# ECD3_MMR_ICONT register map
Vendor: Texas Instruments
Peripheral module from a debugger description file (folder omap5430_ES2_PUBLIC).
Registers are 32-bit, access per field, reset 0x0 unless marked. A register's access mark holds for its fields unless they carry their own. Offsets are as the file gives them; lines under a group give offsets from that group; [hi:lo] are bit positions; {n}, {i} and the like mark numbered series; 'fields as' and 'values as' point back to an identical list; <NAME> marks a mode.

## ECD3_MMR_ICONT (part 1 of 2)
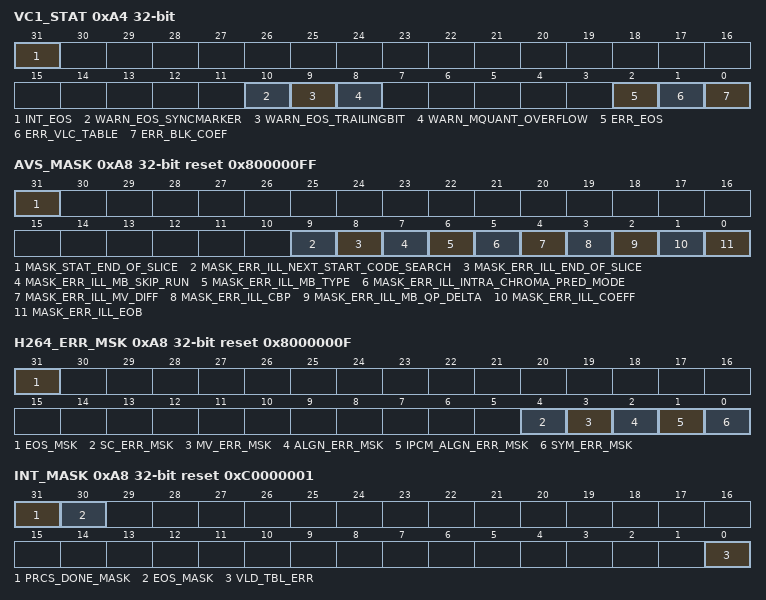
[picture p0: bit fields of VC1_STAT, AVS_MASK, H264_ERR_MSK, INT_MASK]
0xA4 VC1_STAT ro
  [31] INT_EOS — Read 0x1: An end-of-slice symbol was found.
  [10] WARN_EOS_SYNCMARKER — This issue is raised when ECD3 cannot find syncmarker header syntax even though a single-bit just after decoding last MB is equal to 0.
  [9] WARN_EOS_TRAILINGBIT — Read 0x1: ECD3 cannot detect the presence of the trailing bit even though the next start code was detected. Even though ECD3 found this defect, the ECD3 will start to search next start code.
  [8] WARN_MQUANT_OVERFLOW — warn_mquant_overflow Read 0x0: MQUANT does not overflow Read 0x1: MQUANT overflow
  [2] ERR_EOS — err_eos indicates an error during search processing for next start code.
  [1] ERR_VLC_TABLE — err_vlc_table indicates when the following irregular cases happen. - Total RUN of AC coefficient exceeds a limit of block size
  [0] ERR_BLK_COEF — err_blk_coef indicates when the following irregular cases happen
0xA8 AVS_MASK ro reset 0x800000FF
  [31] MASK_STAT_END_OF_SLICE — Mask flags correspond to status bits
  [9] MASK_ERR_ILL_NEXT_START_CODE_SEARCH — Mask flags correspond to status bits
  [8] MASK_ERR_ILL_END_OF_SLICE — Mask flags correspond to status bits
  [7] MASK_ERR_ILL_MB_SKIP_RUN — Mask flags correspond to status bits
  [6] MASK_ERR_ILL_MB_TYPE — Mask flags correspond to status bits
  [5] MASK_ERR_ILL_INTRA_CHROMA_PRED_MODE — Mask flags correspond to status bits
  [4] MASK_ERR_ILL_MV_DIFF — Mask flags correspond to status bits
  [3] MASK_ERR_ILL_CBP — Mask flags correspond to status bits
  [2] MASK_ERR_ILL_MB_QP_DELTA — Mask flags correspond to status bits
  [1] MASK_ERR_ILL_COEFF — Mask flags correspond to status bits
  [0] MASK_ERR_ILL_EOB — Mask flags correspond to status bits
0xA8 H264_ERR_MSK reset 0x8000000F — H.264 MASK register
  [31] EOS_MSK ro — EOS_MSK = 1 enables detection of an EOS.
  [4] SC_ERR_MSK ro — SC_ERR_MSK = 0 (fixed) which indicates that int_err will never be issued on detecting start code search error.
  [3] MV_ERR_MSK ro — MV_ERR_MSK = 1 enables detection of mv errors (MV_ERR).
  [2] ALGN_ERR_MSK rw — ALGN_ERR_MSK = 1 enables detection of CABAC alignment bits errors (ALGN_ERR)
  [1] IPCM_ALGN_ERR_MSK rw — IPCM_ALGN_ERR_MSK = 1 enables detection of I_PCM alignment bits errors (IPCM_ALGN_ERR)
  [0] SYM_ERR_MSK ro — SYM_ERR_MSK = 1 enables detections of all other bitstream errors (SYM_ERR).
0xA8 INT_MASK ro reset 0xC0000001
  [31] PRCS_DONE_MASK — Mask register for prcs_done signal. 0: PRCS_DONE signal disable. 1: PRCS_DONE signal enable
  [30] EOS_MASK — Mask register for eos_done pulse signal 0: EOS_DONE signal disable. 1: EOS_DONE signal enable.
  [0] VLD_TBL_ERR — Mask register for control of error interrupt assertion. 0: no error interrupt is asserted though condition is hit. 1: error interrupt is asserted if condition is hit.
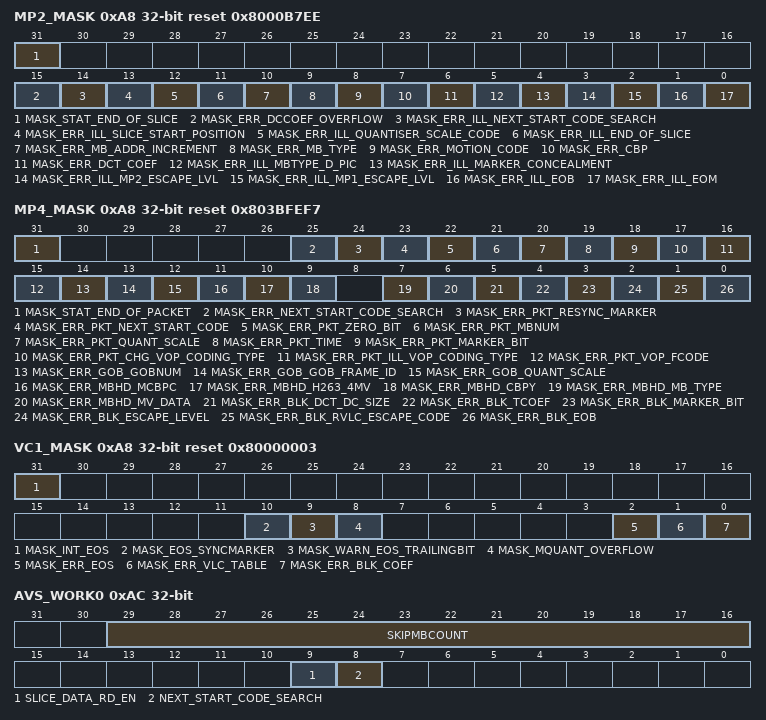
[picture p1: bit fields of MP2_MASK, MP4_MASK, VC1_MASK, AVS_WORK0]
0xA8 MP2_MASK reset 0x8000B7EE
  [31] MASK_STAT_END_OF_SLICE ro — Mask flags correspond to status bits
  [15] MASK_ERR_DCCOEF_OVERFLOW ro — Mask flags correspond to status bits
  [14] MASK_ERR_ILL_NEXT_START_CODE_SEARCH ro — Mask flags correspond to status bits
  [13] MASK_ERR_ILL_SLICE_START_POSITION ro — Mask flags correspond to status bits
  [12] MASK_ERR_ILL_QUANTISER_SCALE_CODE ro — Mask flags correspond to status bits
  [11] MASK_ERR_ILL_END_OF_SLICE ro — Mask flags correspond to status bits
  [10] MASK_ERR_MB_ADDR_INCREMENT ro — Mask flags correspond to status bits
  [9] MASK_ERR_MB_TYPE ro — Mask flags correspond to status bits
  [8] MASK_ERR_MOTION_CODE ro — Mask flags correspond to status bits
  [7] MASK_ERR_CBP ro — Mask flags correspond to status bits
  [6] MASK_ERR_DCT_COEF ro — Mask flags correspond to status bits
  [5] MASK_ERR_ILL_MBTYPE_D_PIC ro — Mask flags correspond to status bits
  [4] MASK_ERR_ILL_MARKER_CONCEALMENT rw — Mask flags correspond to status bits
  [3] MASK_ERR_ILL_MP2_ESCAPE_LVL ro — Mask flags correspond to status bits
  [2] MASK_ERR_ILL_MP1_ESCAPE_LVL ro — Mask flags correspond to status bits
  [1] MASK_ERR_ILL_EOB ro — Mask flags correspond to status bits
  [0] MASK_ERR_ILL_EOM rw — Mask flags correspond to status bits
0xA8 MP4_MASK reset 0x803BFEF7
  [31] MASK_STAT_END_OF_PACKET ro — Mask flags correspond to status bits
  [25] MASK_ERR_NEXT_START_CODE_SEARCH ro — Mask flags correspond to status bits
  [24] MASK_ERR_PKT_RESYNC_MARKER ro — Mask flags correspond to status bits
  [23] MASK_ERR_PKT_NEXT_START_CODE ro — Mask flags correspond to status bits
  [22] MASK_ERR_PKT_ZERO_BIT ro — Mask flags correspond to status bits
  [21] MASK_ERR_PKT_MBNUM ro — Mask flags correspond to status bits
  [20] MASK_ERR_PKT_QUANT_SCALE ro — Mask flags correspond to status bits
  [19] MASK_ERR_PKT_TIME ro — Mask flags correspond to status bits
  [18] MASK_ERR_PKT_MARKER_BIT rw — Mask flags correspond to status bits
  [17] MASK_ERR_PKT_CHG_VOP_CODING_TYPE ro — Mask flags correspond to status bits
  [16] MASK_ERR_PKT_ILL_VOP_CODING_TYPE ro — Mask flags correspond to status bits
  [15] MASK_ERR_PKT_VOP_FCODE ro — Mask flags correspond to status bits
  [14] MASK_ERR_GOB_GOBNUM ro — Mask flags correspond to status bits
  [13] MASK_ERR_GOB_GOB_FRAME_ID ro — Mask flags correspond to status bits
  [12] MASK_ERR_GOB_QUANT_SCALE ro — Mask flags correspond to status bits
  [11] MASK_ERR_MBHD_MCBPC ro — Mask flags correspond to status bits
  [10] MASK_ERR_MBHD_H263_4MV ro — Mask flags correspond to status bits
  [9] MASK_ERR_MBHD_CBPY ro — Mask flags correspond to status bits
  [7] MASK_ERR_MBHD_MB_TYPE ro — Mask flags correspond to status bits
  [6] MASK_ERR_MBHD_MV_DATA ro — Mask flags correspond to status bits
  [5] MASK_ERR_BLK_DCT_DC_SIZE ro — Mask flags correspond to status bits
  [4] MASK_ERR_BLK_TCOEF ro — Mask flags correspond to status bits
  [3] MASK_ERR_BLK_MARKER_BIT rw — Mask flags correspond to status bits
  [2] MASK_ERR_BLK_ESCAPE_LEVEL ro — Mask flags correspond to status bits
  [1] MASK_ERR_BLK_RVLC_ESCAPE_CODE ro — Mask flags correspond to status bits
  [0] MASK_ERR_BLK_EOB ro — Mask flags correspond to status bits
0xA8 VC1_MASK reset 0x80000003
  [31] MASK_INT_EOS ro
  [10] MASK_EOS_SYNCMARKER ro
  [9] MASK_WARN_EOS_TRAILINGBIT ro — Reserved
  [8] MASK_MQUANT_OVERFLOW rw — Mask flags correspond to status bits
  [2] MASK_ERR_EOS ro — Mask flags correspond to status bits
  [1] MASK_ERR_VLC_TABLE ro — Mask flags correspond to status bits
  [0] MASK_ERR_BLK_COEF ro — Mask flags correspond to status bits
0xAC AVS_WORK0
  [29:16] SKIPMBCOUNT rw — SkipMbCount This field specifies SkipMbCount described in AVS standard section 9.3.
  [9] SLICE_DATA_RD_EN rw — Slice data read enable flag 0: slice data is read only at the first macroblock in a slice 1: slice data is read at every macroblocks AVS RTL can reduce the cycle not to read slice data in non-first macroblock in a slice by clearing this flag to 0. For normal bitstream encode and decode case, this bit must be cleared to 0 for faster execution of AVS. But if user wants to start processing from the non-first macroblock in a slice, user must set this flag to 1. This flag is applicable for RTL, not C-model. C-model always read slice data because there is no static data register in C-model. Then, the behavior between RTL and C-model is not matched if this flag is cleared to 0 and the processing is started from the non-first macroblock in a slice.
  [8] NEXT_START_CODE_SEARCH rw — next_start_code_search This field specifies ECD starts start code search or not when error is occurred. 0: non-search 1: search
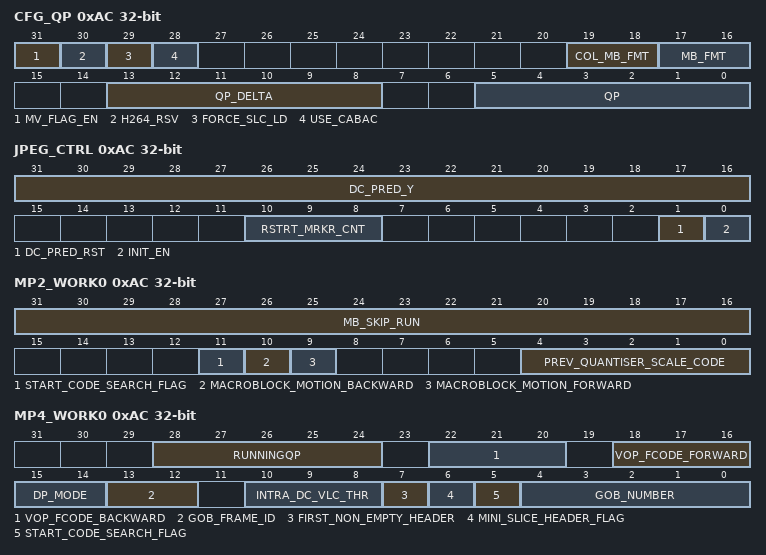
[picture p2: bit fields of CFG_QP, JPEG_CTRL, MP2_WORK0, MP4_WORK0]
0xAC CFG_QP
  [31] MV_FLAG_EN rw — MV_FLAG_EN =1 enables motion vector and reference index comparison in decoding. If MV_FLAG_EN=1, motion vectors and reference indices are compared and results are reflected to mv_equal_flag_l0/1 and refidx_equal_flag_l0/1 in MBinfo. In encoding, even if MV_FLAG_EN=1, the comparisons are not executed.
  [30] H264_RSV rw — Reserved for future use
  [29] FORCE_SLC_LD rw — FORCE_SLC_LD = 1 forces slice information data loading from memory for each macroblock process. If this bit is equal to 0, slice information data is loaded only when the current macroblock is the first macroblock in the slice. This feature is for debug use only so as to enable modifying slice information in the middle of slice processing. Usually, it is necessary at the beginning of each slice, and this bit must be cleared to save cycle counts for data loading
  [28] USE_CABAC ro — USE_CABAC = 1 indicates that the CABAC is in use for entropy coding. If the value is equal to 0, CAVLC is used. The ECD3 automatically loads the value from slice information onto this register.
  [19:18] COL_MB_FMT ro — COL_MB_FMT indicates the macroblock header format type for the co-located macroblock data. 00b : Bi-16-MV format 01b : 16-MV format 10b : Bi-4-MV format 11b : The reserved ECD3 automatically loads the value from slice information onto this register
  [17:16] MB_FMT ro — MB_FMT indicates the macroblock header format type for the current macroblock and neighboring macroblocks in the current picture. 00b : Bi-16-MV format 01b : 16-MV format 10b : Bi-4-MV format 11b : The reserved ECD3 automatically loads the value from slice information onto this register
  [13:8] QP_DELTA rw — QP_DELTA is equal to mb_qp_delta of the last macroblock decoded or encoded. This register value is maintained by the ECD3, so that the user does not set up the value
  [5:0] QP rw — QP is equal to the quantizer parameter for the last macroblock decoded or encoded. This register value is maintained by the ECD3
0xAC JPEG_CTRL — JPEG Control register
  [31:16] DC_PRED_Y rw — Luminance DC prediction value is stored in register. H/W regards this value as previous DC value (source of DC prediction) except in a block just after restart marker. In case other than tests, this register value must not be written.
  [10:8] RSTRT_MRKR_CNT ro — Restart marker counter value (during encoding only) is reflected in this register. In decoding, please ignore.
  [1] DC_PRED_RST rw — If this register bit is high, DC prediction for the first block of the current MCU is not executed. This register bit must be used in case of error recovery, and valid in decoder. In encoder, the configured value is ignored. The configured value is automatically reset immediately after the user configures this bit to 1. 0: DC prediction is executed. 1: DC prediction is reset.
  [0] INIT_EN rw — This bit controls initialization of JPEG core on ECD module. If this bit is high, all counter values are reset and all address pointer for picture configuration data and Huffman code tables are loaded. Please notice that this bit must be activated once before starting processing of ECD module, and after all configuration of memory address is done. During period that this bit is high, any writing access is ignored. 0: initialize disable. 1: initialize start.
0xAC MP2_WORK0
  [31:16] MB_SKIP_RUN rw — Specifies the number of macroblocks to be skipped
  [11] START_CODE_SEARCH_FLAG rw — Specifies whether ECD starts searching next start code or not when error is occurred in decoding. 0: Not search next start code 1: Search next start code In encoding, this field must be 0.
  [10] MACROBLOCK_MOTION_BACKWARD rw — Specifies macroblock_motion_backward described in MPEG-2 standard section 6.3.17.1.
  [9] MACROBLOCK_MOTION_FORWARD rw — Specifies macroblock_motion_forward described in MPEG-2 standard section 6.3.17.1.
  [4:0] PREV_QUANTISER_SCALE_CODE rw — Specifies previous macroblock's quantizer_scale_code described in MPEG-2 standard section 6.3.16
0xAC MP4_WORK0
  [28:24] RUNNINGQP rw — This field is used for reserving runningQp for the next macroblock, not showing the current macroblock's quantizer_scale. At the beginning of a VOP, ECD copies from vop_quant in VOP header information
  [22:20] VOP_FCODE_BACKWARD rw — These fields specify vop_fcode_forward and vop_fcode_backward updated at packet header. In decoding, at the beginning of a VOP, ECD copies from vop_fcode_forward and vop_fcode_backward in VOP header information to these fields. ECD updates these fields at packet header decoding. In encoding, this field is not used and must be fixed to 0. ECD uses vop_fcode_forward and vop_fcode_backward in macroblock header information
  [18:16] VOP_FCODE_FORWARD rw — These fields specify vop_fcode_forward and vop_fcode_backward updated at packet header. In decoding, at the beginning of a VOP, ECD copies from vop_fcode_forward and vop_fcode_backward in VOP header information to these fields. ECD updates these fields at packet header decoding. In encoding, this field is not used and must be fixed to 0. ECD uses vop_fcode_forward and vop_fcode_backward in macroblock header information
  [15:14] DP_MODE rw — This field indicates which data is encoding or decoding in data partitioning mode. Host must reset this field to 0 at the beginning of a VOP. ECD updates automatically during a VOP. This field is reset to 0 at the beginning of a slice, and ECD automatically sets to 1 when it decodes or encodes dc_marker or motion_marker, and also automatically sets to 2 when it decodes all texture header. 0: GOB header or motion and header information processing 1: texture header processing 2: TCOEF processing or packet header, In non data partitioning mode, this field is not used
  [13:12] GOB_FRAME_ID rw — This field specifies gob_frame_id which is updated at gob header. In decoding, when first_non_empty_header = 1, decoded gob_frame_id in packet header is compared with gob_frame_id in local information, and if it differs, ECD detects error named 'gob_frame_id is changed'. When first_non_empty_header = 0, decoded gob_frame_id is written to this field. If GOB header is not existed in a VOP, gob_frame_id is 0. In encoding, this field is not used and must be fixed to 0. ECD uses gob_frame_id in macroblock header information
  [10:8] INTRA_DC_VLC_THR rw — This is a 3-bit code that specifies a threshold value of quantizer scale used to switch between two VLC's for coding of Intra DC coefficients. In decoding, at the beginning of a VOP, ECD copies from intra_dc_vlc_thr in VOP header information to the field. ECD updates the fields at packet header decoding. In encoding, this field is not used. ECD uses intra_dc_vlc_thr in macroblock header information
  [7] FIRST_NON_EMPTY_HEADER rw — This is the flag to indicate the first non empty GOB header or not. In decoding, ECD sets 1 to this field at the beginning of VOP. ECD sets to 0 if ECD encounters the first non-empty GOB header. In encoding, this field is not used and must be fixed to 0
  [6] MINI_SLICE_HEADER_FLAG rw — In H.263 decoding, this field specifies whether the current slice header is mini slice header or not. After decoding slice header, this field is automatically reset to 0 by the ECD3. 0: non mini slice header 1: mini slice header Otherwise, this field must be 0
  [5] START_CODE_SEARCH_FLAG rw — In decoding, this field specifies whether ECD starts searching next_start_code and resync_marker or not when error is occurred in decoding. 0: Not search next start code and resync marker 1: Search next start code and resync marker In encoding, this field must be 0
  [4:0] GOB_NUMBER rw — In decoding, this field specifies gob_number of the current macroblock. In encoding, this field is not used and must be fixed to 0
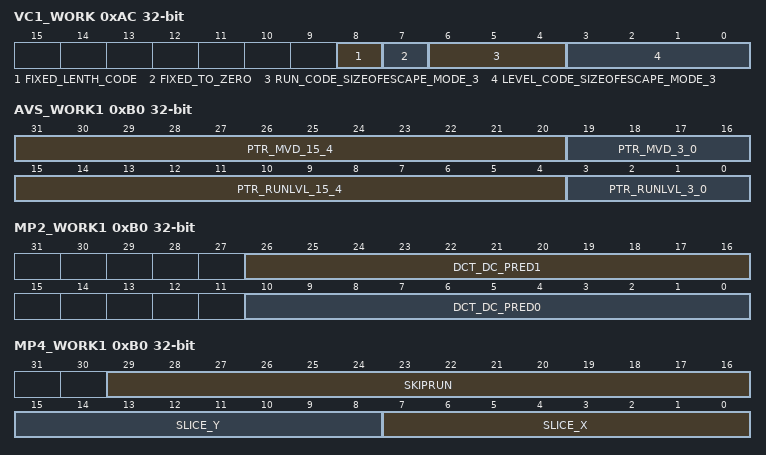
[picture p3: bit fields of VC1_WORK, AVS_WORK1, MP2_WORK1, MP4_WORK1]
0xAC VC1_WORK
  [8] FIXED_LENTH_CODE rw — Presence of Fixed Length Code (escape mode 3) Setting 1 specifies the first case of escape mode 3 in a frame. This register is cleared when found ESCAPE3. 0: non-first case of escape mode 3 in frame 1: first case of escape mode 3 in frame
  [7] FIXED_TO_ZERO ro
  [6:4] RUN_CODE_SIZEOFESCAPE_MODE_3 rw — Run code size of escape mode 3 Run code size of escape mode 3 In decoding, this register is automatically updated when presence of fixed length code is cleared to 0
  [3:0] LEVEL_CODE_SIZEOFESCAPE_MODE_3 rw — Level code size of escape mode 3 Level code size of escape mode 3 In decoding, this register is automatically updated when presence of fixed length code is cleared to 0
0xB0 AVS_WORK1
  [31:20] PTR_MVD_15_4 rw — PTR_MVD Start address of temporary MVD info. This value must be multiple of 8.
  [19:16] PTR_MVD_3_0 ro — PTR_MVD Start address of temporary MVD info. This value must be multiple of 8.
  [15:4] PTR_RUNLVL_15_4 rw — PTR_RUNLVL Start address of temporary run level info. This value must be multiple of 8.
  [3:0] PTR_RUNLVL_3_0 ro — PTR_RUNLVL Start address of temporary run level info. This value must be multiple of 8.
0xB0 CDC_VP_4
  [15:3] ACPREDPTR_15_3 rw — ACPREDPTR I picture except simple/main I picture
0xB0 MP2_WORK1
  [26:16] DCT_DC_PRED1 rw — In decoding, this value specifies dct_dc_pred[1] described in MPEG-2 standard section 7.2.1. In encoding, this value is fixed to 0
  [10:0] DCT_DC_PRED0 rw — In decoding, this value specifies dct_dc_pred[0] described in MPEG-2 standard section 7.2.1. In encoding, this value is fixed to 0
0xB0 MP4_WORK1
  [29:16] SKIPRUN rw — In the case of B-VOP decoding, if decoded macroblock_number in video_packet_header &gt; the macroblock address counter, ECD notices the macroblocks from the macroblock address counter to macroblock_number -1 would be not_coded macroblock. ECD reserves (macroblock_number - MB_NUM) value to SKIP_NUM to skip macroblocks. In the other cases, this field must be 0
  [15:8] SLICE_Y rw — In data partitioning, this field shows the position of the first macroblock in a slice. Otherwise, this field must be 0. This is for data partitioning to recover the first macroblock position after texture encoding and decoding
  [7:0] SLICE_X rw — In data partitioning, this field shows the position of the first macroblock in a slice. Otherwise, this field must be 0. This is for data partitioning to recover the first macroblock position after texture encoding and decoding
0xB0 SKIP_RUN
  [15:0] SKIP_RUN_NB rw — SKIP_RUN_NB indicates the number of skipped macroblocks left in CAVLC. This register is maintained by the ECD3.
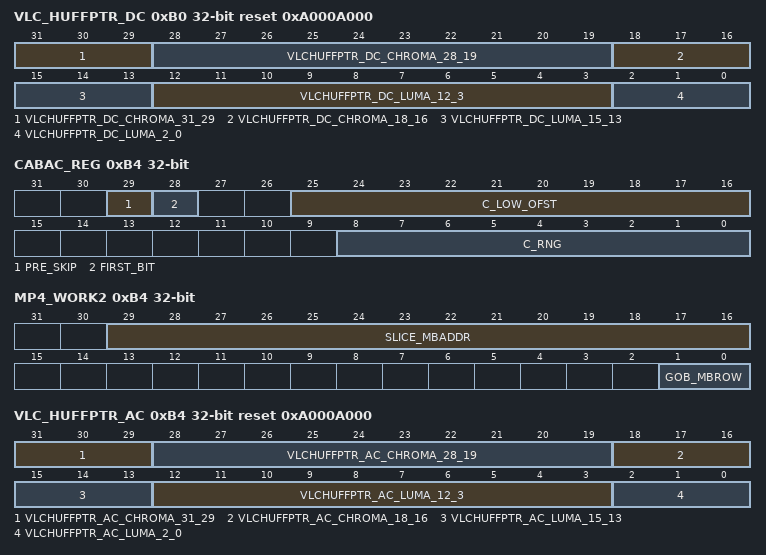
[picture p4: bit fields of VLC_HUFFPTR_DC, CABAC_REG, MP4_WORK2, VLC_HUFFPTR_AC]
0xB0 VLC_HUFFPTR_DC reset 0xA000A000 — Pointers to Huffman table for VLC DC components
  [31:29] VLCHUFFPTR_DC_CHROMA_31_29 ro — Indicating start address of Huffman table for VLC DC Chroma. The address value must be aligned to 64-bit word boundary
  [28:19] VLCHUFFPTR_DC_CHROMA_28_19 rw — Indicating start address of Huffman table for VLC DC Chroma. The address value must be aligned to 64-bit word boundary
  [18:16] VLCHUFFPTR_DC_CHROMA_18_16 ro — Indicating start address of Huffman table for VLC DC Chroma. The address value must be aligned to 64-bit word boundary
  [15:13] VLCHUFFPTR_DC_LUMA_15_13 ro — Indicating start address of Huffman table for VLC DC-luma. The address value must be aligned to 64-bit word boundary
  [12:3] VLCHUFFPTR_DC_LUMA_12_3 rw — Indicating start address of Huffman table for VLC DC-luma. The address value must be aligned to 64-bit word boundary
  [2:0] VLCHUFFPTR_DC_LUMA_2_0 ro — Indicating start address of Huffman table for VLC DC-luma. The address value must be aligned to 64-bit word boundary
0xB4 CABAC_REG
  [29] PRE_SKIP rw — PRE_SKIP = 1 indicates that both top and bottom macroblocks in MB-AFF mode decoding are skipped. This flag is not used in encoding or in CAVLC mode
  [28] FIRST_BIT rw — FIRST_BIT = 1 indicates that the next bit put by CABAC is the first bit since the last CABAC initialization. This register is automatically set by CABAC encoder. This flag is ignored in decoding or in CAVLC mode
  [25:16] C_LOW_OFST rw — C_LOW_OFST is equal to codILow in encoding, and codIOffset in decoding. codILow shall be in the range of [0x000, 0x3FF], and codIOffset in [0x000, 0x1FF]. This field is ignored in CAVLC
  [8:0] C_RNG rw — C_RNG is equal to codIRange. This field is ignored in CAVLC
0xB4 CDC_VP_5
  [15:3] OVERFLAGPTR_15_3 rw — OVERFLAGPTR I picture except simple/main I picture
0xB4 MP2_WORK2
  [10:0] DCT_DC_PRED2 rw — In decoding, this value specifies dct_dc_pred[2] described in MPEG-2 standard section 7.2.1. In encoding, this value is fixed to 0
0xB4 MP4_WORK2
  [29:16] SLICE_MBADDR rw — In data partition decoding, this field shows the macroblock address of the first macroblock in the current slice. ECD updates this field at the beginning of a slice. The value is used to recover the first macroblock position in data partitioning. Otherwise, this field must be 0
  [1:0] GOB_MBROW rw — In the case h263_mode = 1 and decoding, this field shows the vertical position of current macroblock in a slice or GOB. For example gob_mbrow = 0 means the current macroblock is in the first row of the current slice or GOB. In the other cases, this field is fixed to 0
0xB4 VLC_HUFFPTR_AC reset 0xA000A000 — Pointers to Huffman table for VLC AC components
  [31:29] VLCHUFFPTR_AC_CHROMA_31_29 ro — Indicating start address of Huffman table for VLC AC Chroma. The address value must be aligned to 64-bit word boundary
  [28:19] VLCHUFFPTR_AC_CHROMA_28_19 rw — Indicating start address of Huffman table for VLC AC Chroma. The address value must be aligned to 64-bit word boundary
  [18:16] VLCHUFFPTR_AC_CHROMA_18_16 ro — Indicating start address of Huffman table for VLC AC Chroma. The address value must be aligned to 64-bit word boundary
  [15:13] VLCHUFFPTR_AC_LUMA_15_13 ro — Indicating start address of Huffman table for VLC AC-luma. The address value must be aligned to 64-bit word boundary
  [12:3] VLCHUFFPTR_AC_LUMA_12_3 rw — Indicating start address of Huffman table for VLC AC-luma. The address value must be aligned to 64-bit word boundary
  [2:0] VLCHUFFPTR_AC_LUMA_2_0 ro — Indicating start address of Huffman table for VLC AC-luma. The address value must be aligned to 64-bit word boundary
0xB8 CDC_VP_6
  [15:3] MVMODEPTR_15_3 rw — MVMODEPTR Progressive P picture
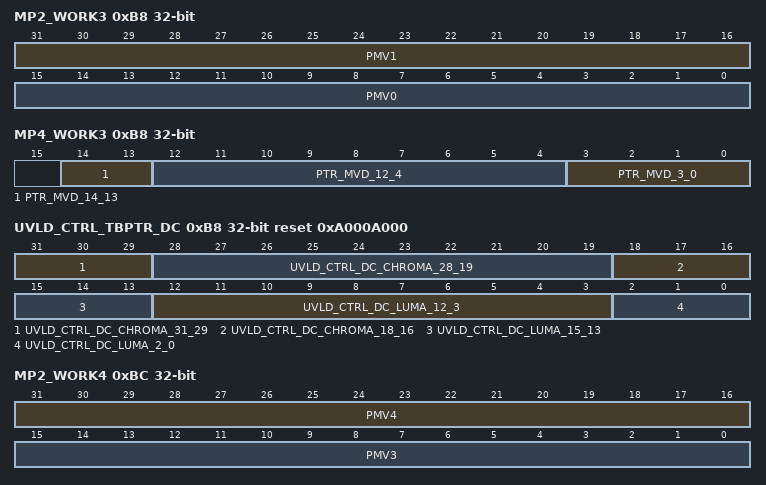
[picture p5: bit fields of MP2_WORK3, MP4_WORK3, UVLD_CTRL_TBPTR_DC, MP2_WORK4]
0xB8 MP2_WORK3 rw
  [31:16] PMV1 — Specifies PMV[0][0][1] described in MPEG-2 standard section 7.6.3. They are half-pel precision
  [15:0] PMV0 — Specifies PMV[0[0][0] described in MPEG-2 standard section 7.6.3. They are half-pel precision
0xB8 MP4_WORK3
  [14:13] PTR_MVD_14_13 ro — This field specifies temporary MVD data pointer. Temporary MVD data must be located at ECDWBUF
  [12:4] PTR_MVD_12_4 rw — This field specifies temporary MVD data pointer. Temporary MVD data must be located at ECDWBUF
  [3:0] PTR_MVD_3_0 ro — This field specifies temporary MVD data pointer. Temporary MVD data must be located at ECDWBUF
0xB8 SYM_CNT rw
  [31:0] SYM_CNT_NB — SYM_CNT_NB is equal to the total number of CABAC bin symbols encoded since the last CABAC initialization. This register is reset to 0 when H.264 core is invoked for a first macroblock in a slice. This register is not used in decoding or in CAVLC mode. This register is maintained by the ECD3
0xB8 UVLD_CTRL_TBPTR_DC reset 0xA000A000 — Pointers to control table for UVLD DC components
  [31:29] UVLD_CTRL_DC_CHROMA_31_29 ro — Indicating start address of control table for UVLD DC-chroma. The address value must be aligned to 64-bit word boundary
  [28:19] UVLD_CTRL_DC_CHROMA_28_19 rw — Indicating start address of control table for UVLD DC-chroma. The address value must be aligned to 64-bit word boundary
  [18:16] UVLD_CTRL_DC_CHROMA_18_16 ro — Indicating start address of control table for UVLD DC-chroma. The address value must be aligned to 64-bit word boundary
  [15:13] UVLD_CTRL_DC_LUMA_15_13 ro — Indicating start address of control table for UVLD DC-luma. The address value must be aligned to 64-bit word boundary.
  [12:3] UVLD_CTRL_DC_LUMA_12_3 rw — Indicating start address of control table for UVLD DC-luma. The address value must be aligned to 64-bit word boundary.
  [2:0] UVLD_CTRL_DC_LUMA_2_0 ro — Indicating start address of control table for UVLD DC-luma. The address value must be aligned to 64-bit word boundary.
0xBC BITS_OSTD rw
  [31:0] BITS_OSTD_NB — BITS_OSTD_NB is equal to the total number of outstanding bits in CABAC encoder. This register is not used in decoding or in CAVLC mode. This register is maintained by the ECD3
0xBC CDC_VP_7
  [15:3] SKIPMBPTR_15_3 rw — SKIPMBPTR Progressive P/B picture, Interlace Frame P/B picture
0xBC MP2_WORK4 rw
  [31:16] PMV4 — Specifies PMV[0][1][1] described in MPEG-2 standard section 7.6.3. They are half-pel precision
  [15:0] PMV3 — Specifies PMV[0][1][0] described in MPEG-2 standard section 7.6.3. They are half-pel precision
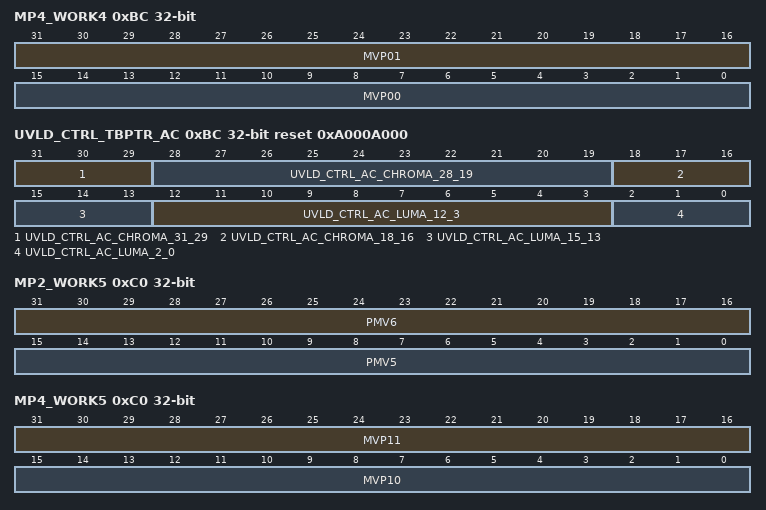
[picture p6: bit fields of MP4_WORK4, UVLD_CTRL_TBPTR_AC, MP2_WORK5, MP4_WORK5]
0xBC MP4_WORK4 rw
  [31:16] MVP01 — MVP[0][1]: Motion Vector Predictors for B-VOP (field forward top motion vector predictor)
  [15:0] MVP00 — MVP[0][0]: Motion Vector Predictors for B-VOP (field forward top motion vector predictor)
0xBC UVLD_CTRL_TBPTR_AC reset 0xA000A000 — Pointers to control table for UVLD AC components
  [31:29] UVLD_CTRL_AC_CHROMA_31_29 ro — Indicating start address of control table for UVLD AC-chroma. The address value must be aligned to 64-bit word boundary
  [28:19] UVLD_CTRL_AC_CHROMA_28_19 rw — Indicating start address of control table for UVLD AC-chroma. The address value must be aligned to 64-bit word boundary
  [18:16] UVLD_CTRL_AC_CHROMA_18_16 ro — Indicating start address of control table for UVLD AC-chroma. The address value must be aligned to 64-bit word boundary
  [15:13] UVLD_CTRL_AC_LUMA_15_13 ro — Indicating start address of control table for UVLD AC-luma. The address value must be aligned to 64-bit word boundary
  [12:3] UVLD_CTRL_AC_LUMA_12_3 rw — Indicating start address of control table for UVLD AC-luma. The address value must be aligned to 64-bit word boundary
  [2:0] UVLD_CTRL_AC_LUMA_2_0 ro — Indicating start address of control table for UVLD AC-luma. The address value must be aligned to 64-bit word boundary
0xC0 CDC_VP_8
  [15:3] DIRECTPT_15_3 rw — DIRECTPTR Progressive B picture, Interlace Frame B picture
0xC0 MP2_WORK5 rw
  [31:16] PMV6 — Specifies PMV[1][0][1] described in MPEG-2 standard section 7.6.3. They are half-pel precision
  [15:0] PMV5 — Specifies PMV[1][0][0] described in MPEG-2 standard section 7.6.3. They are half-pel precision
0xC0 MP4_WORK5 rw
  [31:16] MVP11 — MVP[1][1]: Motion Vector Predictors for B-VOP (field forward bottom motion vector predictor)
  [15:0] MVP10 — MVP[1][0]: Motion Vector Predictors for B-VOP (field forward bottom motion vector predictor)
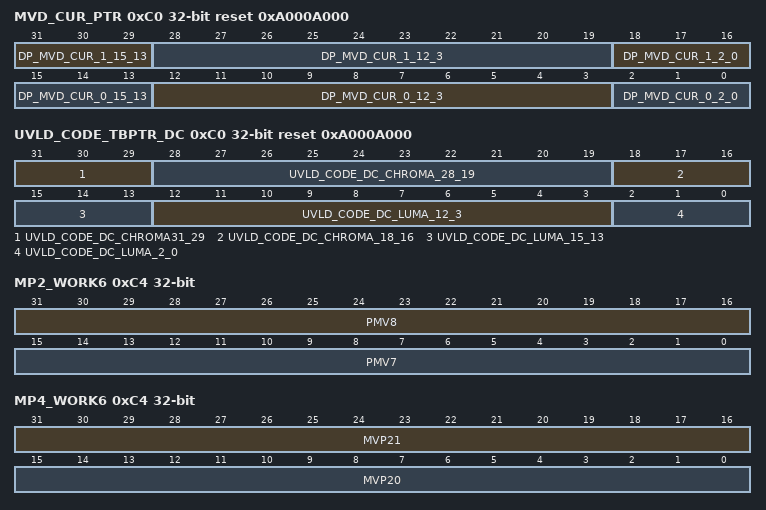
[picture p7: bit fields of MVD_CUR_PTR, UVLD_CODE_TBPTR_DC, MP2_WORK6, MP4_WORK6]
0xC0 MVD_CUR_PTR reset 0xA000A000
  [31:29] DP_MVD_CUR_1_15_13 ro — DP_MVD_CUR_1 specifies the pointer to motion vector delta data for bottom macroblock of the current macroblock pair. This register is updated by the ECD3 for each macroblock. This register is used only when in MBAFF mode
  [28:19] DP_MVD_CUR_1_12_3 rw — DP_MVD_CUR_1 specifies the pointer to motion vector delta data for bottom macroblock of the current macroblock pair. This register is updated by the ECD3 for each macroblock. This register is used only when in MBAFF mode
  [18:16] DP_MVD_CUR_1_2_0 ro — DP_MVD_CUR_1 specifies the pointer to motion vector delta data for bottom macroblock of the current macroblock pair. This register is updated by the ECD3 for each macroblock. This register is used only when in MBAFF mode
  [15:13] DP_MVD_CUR_0_15_13 ro — DP_MVD_CUR_0 specifies the pointer to motion vector delta data for the current macroblock or top macroblock of the current macroblock pair. This register is updated by the ECD3 for each macroblock
  [12:3] DP_MVD_CUR_0_12_3 rw — DP_MVD_CUR_0 specifies the pointer to motion vector delta data for the current macroblock or top macroblock of the current macroblock pair. This register is updated by the ECD3 for each macroblock
  [2:0] DP_MVD_CUR_0_2_0 ro — DP_MVD_CUR_0 specifies the pointer to motion vector delta data for the current macroblock or top macroblock of the current macroblock pair. This register is updated by the ECD3 for each macroblock
0xC0 UVLD_CODE_TBPTR_DC reset 0xA000A000 — Pointers to code table for UVLD DC components
  [31:29] UVLD_CODE_DC_CHROMA31_29 ro — Indicating start address of code table for UVLD DC-chroma. The address value must be aligned to 64-bit word boundary
  [28:19] UVLD_CODE_DC_CHROMA_28_19 rw — Indicating start address of code table for UVLD DC-chroma. The address value must be aligned to 64-bit word boundary
  [18:16] UVLD_CODE_DC_CHROMA_18_16 ro — Indicating start address of code table for UVLD DC-chroma. The address value must be aligned to 64-bit word boundary
  [15:13] UVLD_CODE_DC_LUMA_15_13 ro — Indicating start address of code table for UVLD DC-luma. The address value must be aligned to 64-bit word boundary
  [12:3] UVLD_CODE_DC_LUMA_12_3 rw — Indicating start address of code table for UVLD DC-luma. The address value must be aligned to 64-bit word boundary
  [2:0] UVLD_CODE_DC_LUMA_2_0 ro — Indicating start address of code table for UVLD DC-luma. The address value must be aligned to 64-bit word boundary
0xC4 CDC_VP_9
  [15:3] FIELDTXPTR_31_3 rw — FIELDTXPTR Interlace Frame I picture
0xC4 MP2_WORK6 rw
  [31:16] PMV8 — Specifies PMV[1][1][1] described in MPEG-2 standard section 7.6.3. They are half-pel precision
  [15:0] PMV7 — Specifies PMV[1][1][0] described in MPEG-2 standard section 7.6.3. They are half-pel precision
0xC4 MP4_WORK6 rw
  [31:16] MVP21 — MVP[2][1]: Motion Vector Predictors for B-VOP (field backward top motion vector predictor)
  [15:0] MVP20 — MVP[2][0]: Motion Vector Predictors for B-VOP (field backward top motion vector predictor)
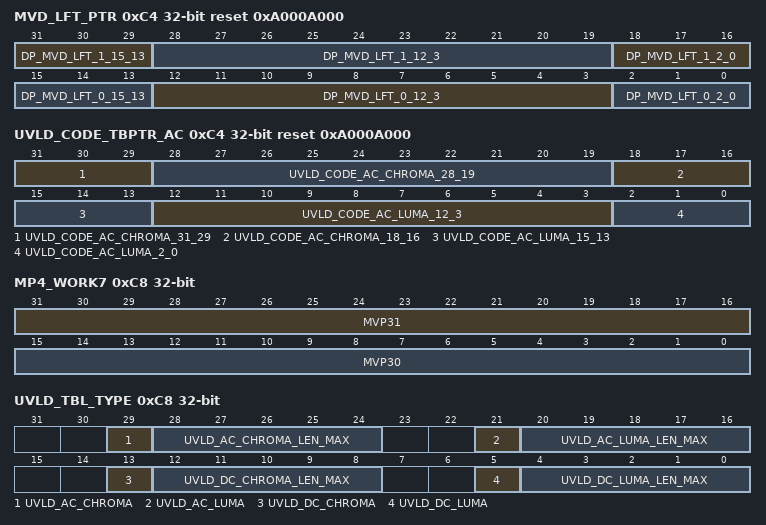
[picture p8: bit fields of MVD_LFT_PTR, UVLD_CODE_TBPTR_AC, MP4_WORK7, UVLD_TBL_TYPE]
0xC4 MVD_LFT_PTR reset 0xA000A000
  [31:29] DP_MVD_LFT_1_15_13 ro — DP_MVD_LFT_1 specifies the pointer to motion vector delta data for bottom macroblock of the left macroblock pair. This register is updated by the ECD3 for each macroblock. This register is used only when in MBAFF mode
  [28:19] DP_MVD_LFT_1_12_3 rw — DP_MVD_LFT_1 specifies the pointer to motion vector delta data for bottom macroblock of the left macroblock pair. This register is updated by the ECD3 for each macroblock. This register is used only when in MBAFF mode
  [18:16] DP_MVD_LFT_1_2_0 ro — DP_MVD_LFT_1 specifies the pointer to motion vector delta data for bottom macroblock of the left macroblock pair. This register is updated by the ECD3 for each macroblock. This register is used only when in MBAFF mode
  [15:13] DP_MVD_LFT_0_15_13 ro — DP_MVD_LFT_0 specifies the pointer to motion vector delta data for the left macroblock or top macroblock of the left macroblock pair. This register is updated by the ECD3 for each macroblock
  [12:3] DP_MVD_LFT_0_12_3 rw — DP_MVD_LFT_0 specifies the pointer to motion vector delta data for the left macroblock or top macroblock of the left macroblock pair. This register is updated by the ECD3 for each macroblock
  [2:0] DP_MVD_LFT_0_2_0 ro — DP_MVD_LFT_0 specifies the pointer to motion vector delta data for the left macroblock or top macroblock of the left macroblock pair. This register is updated by the ECD3 for each macroblock
0xC4 UVLD_CODE_TBPTR_AC reset 0xA000A000 — Pointers to code table for UVLD AC components
  [31:29] UVLD_CODE_AC_CHROMA_31_29 ro — Indicating start address of code table for UVLD AC Chroma. The address value must be aligned to 64-bit word boundary
  [28:19] UVLD_CODE_AC_CHROMA_28_19 rw — Indicating start address of code table for UVLD AC Chroma. The address value must be aligned to 64-bit word boundary
  [18:16] UVLD_CODE_AC_CHROMA_18_16 ro — Indicating start address of code table for UVLD AC Chroma. The address value must be aligned to 64-bit word boundary
  [15:13] UVLD_CODE_AC_LUMA_15_13 ro — Indicating start address of code table for UVLD AC-luma. The address value must be aligned to 64-bit word boundary
  [12:3] UVLD_CODE_AC_LUMA_12_3 rw — Indicating start address of code table for UVLD AC-luma. The address value must be aligned to 64-bit word boundary
  [2:0] UVLD_CODE_AC_LUMA_2_0 ro — Indicating start address of code table for UVLD AC-luma. The address value must be aligned to 64-bit word boundary
0xC8 CDC_VP_A
  [15:3] FWDBITPTR_15_3 rw — FWDBITPTR Interlace Field B picture
0xC8 MP4_WORK7 rw
  [31:16] MVP31 — MVP[3][1]: Motion Vector Predictors for B-VOP (field backward bottom motion vector predictor)
  [15:0] MVP30 — MVP[3][0]: Motion Vector Predictors for B-VOP (field backward bottom motion vector predictor)
0xC8 UVLD_TBL_TYPE — Setting for UVLD code table
  [29] UVLD_AC_CHROMA rw — Indicating type of UVLD code table for AC-chroma data. 0: zero-leading. 1: one-leading.
  [28:24] UVLD_AC_CHROMA_LEN_MAX rw — This data defines maximum code length of universal VLD code table for AC-chroma. The ECD H/W checks this value only in decoder of RAM mode. Maximum value is 16 (0x10), which is restriction of JPEG standard.
  [21] UVLD_AC_LUMA rw — Indicating type of UVLD code table for AC-luma data. 0: zero-leading. 1: one-leading
  [20:16] UVLD_AC_LUMA_LEN_MAX rw — This data defines maximum code length of universal VLD code table for AC-luma. The ECD H/W checks this value only in decoder of RAM mode.
  [13] UVLD_DC_CHROMA rw — Indicating type of UVLD code table for DC-chroma data. 0: zero-leading. 1: one-leading
  [12:8] UVLD_DC_CHROMA_LEN_MAX rw — This data defines maximum code length of universal VLD code table for DC-chroma. The ECD H/W checks this value only in decoder of RAM mode. Maximum value is 16 (0x10), which is restriction of JPEG standard.
  [5] UVLD_DC_LUMA rw — Indicating type of UVLD code table for DC-luma data. 0: zero-leading 1: one-leading
  [4:0] UVLD_DC_LUMA_LEN_MAX rw — This data defines maximum code length of universal VLD code table for DC-luma. The ECD H/W checks this value only in decoder of RAM mode. Maximum value is 16 (0x10), which is restriction of JPEG standard.
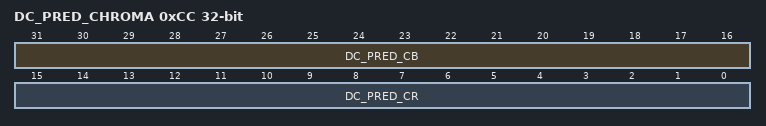
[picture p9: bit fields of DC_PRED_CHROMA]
0xCC DC_PRED_CHROMA rw — JPEG DC PRED Chroma register - TI internal
  [31:16] DC_PRED_CB — Chrominance (Cb) DC prediction value is stored in register. H/W regards this value as previous DC value (source of DC prediction) except in a block just after restart marker. In case other than TI internal test, this register value must not be written externally.
  [15:0] DC_PRED_CR — Chrominance (Cr) DC prediction value is stored in register. H/W regards this value as previous DC value (source of DC prediction) except in a block just after restart marker. In case other than TI internal test, this register value must not be written externally.
{0xF0+4i} CMDP_GPR{i} ro (i=0..2) — Command Processor General Purpose Register {i}
  [31:0] GPR{i} — Command Processor General purpose registers (GPR0, GPR1, and GPR2) are 32-bit registers which can be used freely. They are accessible through these addresses.
